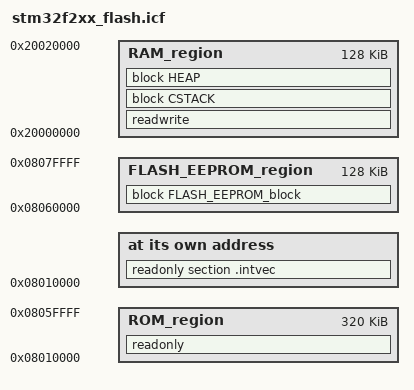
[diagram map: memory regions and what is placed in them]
/*###ICF### Section handled by ICF editor, don't touch! ****/
/*-Editor annotation file-*/
/* IcfEditorFile="$TOOLKIT_DIR$\config\ide\IcfEditor\cortex_v1_0.xml" */
/*-Specials-*/

define symbol __ICFEDIT_intvec_start__ = 0x08010000;
/*-Memory Regions-*/
/*-ROM end is one sector prior to-*/
/*-end of memory:-----------------*/
/*---0x080DFFFF for the IAR board-*/
/*---0x0805FFFF for the DMU380----*/
define symbol __ICFEDIT_region_ROM_start__ = 0x08010000;
define symbol __ICFEDIT_region_ROM_end__   = 0x0805FFFF;

define symbol __ICFEDIT_region_RAM_start__ = 0x20000000;
define symbol __ICFEDIT_region_RAM_end__   = 0x20020000;
/*-Sizes-*/
define symbol __ICFEDIT_size_cstack__ = 0x400;
define symbol __ICFEDIT_size_heap__   = 0x200;
/**** End of ICF editor section. ###ICF###*/


define memory mem with size = 4G;
define region ROM_region   = mem:[from __ICFEDIT_region_ROM_start__   to __ICFEDIT_region_ROM_end__];
define region RAM_region   = mem:[from __ICFEDIT_region_RAM_start__   to __ICFEDIT_region_RAM_end__];

define block CSTACK    with alignment = 8, size = __ICFEDIT_size_cstack__   { };
define block HEAP      with alignment = 8, size = __ICFEDIT_size_heap__     { };

initialize by copy { readwrite };
do not initialize  { section .noinit };

place at address mem:__ICFEDIT_intvec_start__ { readonly section .intvec };

/*-FLASH_EEPROM_start is:---*/
/*---0x080E0000 for the IAR board-*/
/*---0x08060000 for the DMU380----*/
define symbol _region_FLASH_EEPROM_start__   = 0x08060000;

/*-FLASH_EEPROM_end is:---*/
/*---0x080FFFFF for the IAR board-*/
/*---0x0807FFFF for the DMU380----*/
define symbol _region_FLASH_EEPROM_end__     = 0x0807FFFF;

define region FLASH_EEPROM_region   = mem:[from _region_FLASH_EEPROM_start__   to _region_FLASH_EEPROM_end__];
define block FLASH_EEPROM_block { section FLASH_BASED_EEPROM };
place in FLASH_EEPROM_region { block FLASH_EEPROM_block };

place in ROM_region   { readonly };
place in RAM_region   { readwrite,
                        block CSTACK, block HEAP };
